# LPC83x register map
File version: 0.2
CPU: CM0PLUS r0p1, little endian, no MPU, no FPU, 2 interrupt priority bits
Registers are 32-bit, read-write, reset 0x0 unless marked. A register's access mark holds for its fields unless they carry their own. Offsets are from the block's base; lines under a group give offsets from that group; [hi:lo] are bit positions; {n}, {i} and the like mark numbered series; 'fields as' and 'values as' point back to an identical list; <NAME> marks a mode.

## Memory map
0x40000000 WWDT size 0xFFF — Windowed Watchdog Timer (WWDT)
0x40004000 MRT size 0xFFF — Multi-Rate Timer (MRT)
0x40008000 WKT size 0xFFF — Self wake-up timer (WKT)
0x4000C000 SWM size 0xFFF — Switch matrix (SWM)
0x4001C000 ADC size 0xFFF — 12-bit Analog-to-Digital Converter (ADC)
0x40020000 PMU size 0xFFF — Power Management Unit (PMU)
0x40028000 DMATRIGMUX size 0xFFF — DMA trigger mux
0x4002C000 INPUTMUX size 0xFFF — Input multiplexing
0x40040000 FLASHCTRL size 0xFFF — Flash controller
0x40044000 IOCON size 0xFFF — I/O configuration (IOCON)
0x40048000 SYSCON size 0xFFF — System configuration (SYSCON)
0x40050000 I2C0 size 0xFFF — I2C0-bus interface
0x40058000 SPI0 size 0xFFF
0x4005C000 SPI1 size 0xFFF
0x40064000 USART0 size 0xFFF
0x50000000 CRC size 0xFFF — Cyclic Redundancy Check (CRC) engine
0x50004000 SCT size 0xFFF — State Configurable Timer (SCT)
0x50008000 DMA size 0xFFF — DMA controller
0xA0000000 GPIO_PORT size 0x3FFF — General Purpose I/O port (GPIO)
0xA0004000 PIN_INT size 0xFFF — Pin interrupt and pattern match engine

## Interrupts
0 SPI0
1 SPI1
3 UART0 (USART0)
8 I2C0
9 SCT
10 MRT
12 WDT (WWDT)
13 BOD (SYSCON)
14 FLASH (FLASHCTRL)
15 WKT
16 ADC_SEQA (ADC)
17 ADC_SEQB (ADC)
18 ADC_THCMP (ADC)
19 ADC_OVR (ADC)
20 DMA
{n+24} PIN_INT{n} (PIN_INT) (n=0..7)

## WWDT — Windowed Watchdog Timer (WWDT)
Base 0x40000000
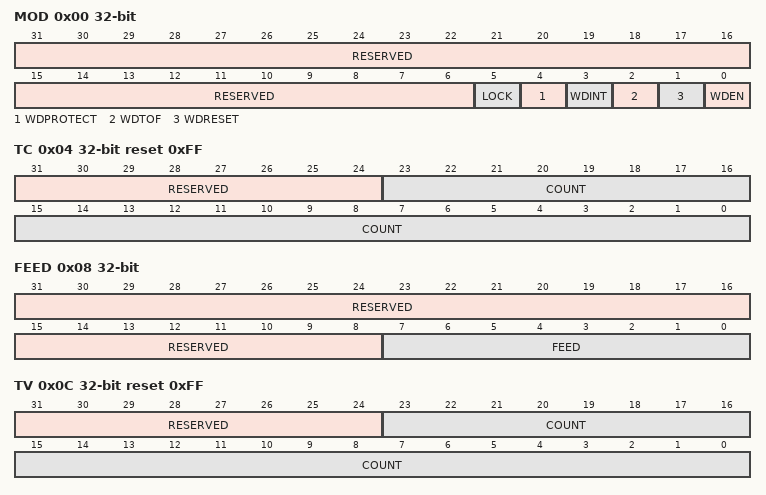
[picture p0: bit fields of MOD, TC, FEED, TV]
0x00 MOD — Watchdog mode register. This register contains the basic mode and status of the Watchdog Timer.
  [31:6] RESERVED — Reserved, user software should not write ones to reserved bits. The value read from a reserved bit is not defined.
  [5] LOCK — A 1 in this bit prevents disabling or powering down the watchdog oscillator. This bit can be set once by software and is only cleared by any reset.
  [4] WDPROTECT — Watchdog update mode. This bit can be set once by software and is only cleared by a reset.
    0=NOTPROTECTED (The watchdog time-out value (TC) can be changed at any time.); 1=PROTECTED (The watchdog time-out value (TC) can be changed only after the counter is below the value of WDWARNINT and WDWINDOW.)
  [3] WDINT — Warning interrupt flag. Set when the timer reaches the value in WDWARNINT. Cleared by software.
  [2] WDTOF — Watchdog time-out flag. Set when the watchdog timer times out, by a feed error, or by events associated with WDPROTECT. Cleared by software. Causes a chip reset if WDRESET = 1.
  [1] WDRESET — Watchdog reset enable bit. Once this bit has been written with a 1 it cannot be rewritten with a 0.
    0=NORESET (A watchdog timeout will not cause a chip reset.); 1=RESET (A watchdog timeout will cause a chip reset.)
  [0] WDEN — Watchdog enable bit. Once this bit has been written with a 1, it cannot be rewritten with a 0.
    0=STOPPED (The watchdog timer is stopped.); 1=RUNNING (The watchdog timer is running.)
0x04 TC reset 0xFF — Watchdog timer constant register. This 24-bit register determines the time-out value.
  [31:24] RESERVED — Reserved, user software should not write ones to reserved bits. The value read from a reserved bit is not defined.
  [23:0] COUNT — Watchdog time-out value.
0x08 FEED wo reset not defined — Watchdog feed sequence register. Writing 0xAA followed by 0x55 to this register reloads the Watchdog timer with the value contained in WDTC.
  [31:8] RESERVED — Reserved, user software should not write ones to reserved bits. The value read from a reserved bit is not defined.
  [7:0] FEED — Feed value should be 0xAA followed by 0x55.
0x0C TV ro reset 0xFF — Watchdog timer value register. This 24-bit register reads out the current value of the Watchdog timer.
  [31:24] RESERVED — Reserved, user software should not write ones to reserved bits. The value read from a reserved bit is not defined.
  [23:0] COUNT — Counter timer value.
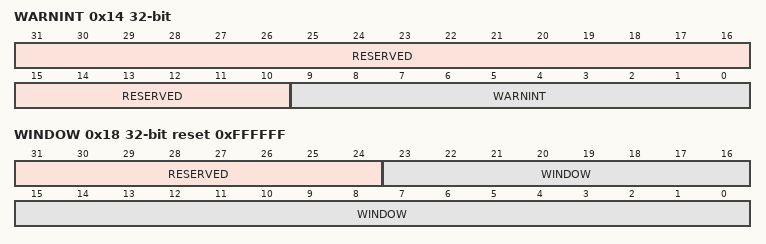
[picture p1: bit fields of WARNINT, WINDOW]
0x14 WARNINT — Watchdog Warning Interrupt compare value.
  [31:10] RESERVED — Reserved, user software should not write ones to reserved bits. The value read from a reserved bit is not defined.
  [9:0] WARNINT — Watchdog warning interrupt compare value.
0x18 WINDOW reset 0xFFFFFF — Watchdog Window compare value.
  [31:24] RESERVED — Reserved, user software should not write ones to reserved bits. The value read from a reserved bit is not defined.
  [23:0] WINDOW — Watchdog window value.
